# TOP_CTRL_TOP_CTRL_50D80000h register map
Vendor: Texas Instruments
Peripheral module from a debugger description file (folder AM263X).
Registers are 32-bit, read-only, reset 0x0 unless marked. A register's access mark holds for its fields unless they carry their own. Offsets are as the file gives them; lines under a group give offsets from that group; [hi:lo] are bit positions; {n}, {i} and the like mark numbered series; 'fields as' and 'values as' point back to an identical list; <NAME> marks a mode.

## TOP_CTRL
{0x10+4i} TOP_CTRL_EFUSE_DIEID{i} (i=0..3) — Register to read DIEID{i}.
  [31:0] EFUSE_DIEID{i}_VAL — EFUSE DieID[{32i+31}:{32i}]
{0x20+4i} TOP_CTRL_EFUSE_UID{i} (i=0..2) — Register to read UID{i}.
  [31:0] EFUSE_UID{i}_VAL — EFUSE UID[{32i+31}:{32i}]
0x2C TOP_CTRL_EFUSE_UID3 — Register to read UID3.
  [23:0] EFUSE_UID3_VAL — EFUSE UID[120:96]
0x30 TOP_CTRL_EFUSE_DEVICE_TYPE — This register indicates Device Type- High Secure : 0b 1100 1100 (0xA).
  [15:0] EFUSE_DEVICE_TYPE_VAL — EFUSE Device Type
0x34 TOP_CTRL_EFUSE_FROM0_CHECKSUM — The register provides checksum for efuse FROM0.
  [31:0] EFUSE_FROM0_CHECKSUM_VAL — 32 bit FROM0 Checksum
0x38 TOP_CTRL_EFUSE_JTAG_USERCODE_ID — Register to read JTAG user IDCODE.
  [31:0] EFUSE_JTAG_USERCODE_ID_VAL — EFUSE JTAG_USER_CODE_ID[31:0];. Denotes part variant
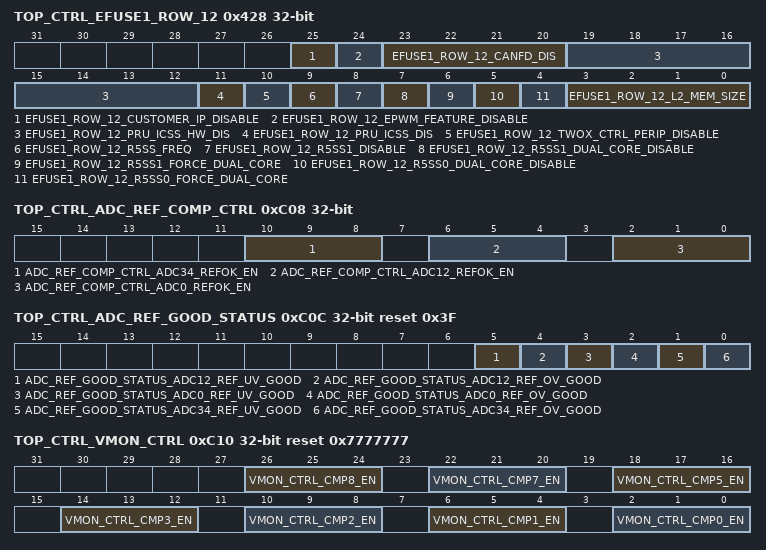
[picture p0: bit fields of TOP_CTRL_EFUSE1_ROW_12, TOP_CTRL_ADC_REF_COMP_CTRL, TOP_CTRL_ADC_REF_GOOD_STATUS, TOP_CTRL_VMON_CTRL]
0x428 TOP_CTRL_EFUSE1_ROW_12 — This register provides details on EFUSE values written into Row 12.
  [25] EFUSE1_ROW_12_CUSTOMER_IP_DISABLE — Customer IP set control0 - All IPs enabled1 - Customer IP set disabled [PWM24-31,CMPSSA6-9,CMPSSB6-9 disabled]
  [24] EFUSE1_ROW_12_EPWM_FEATURE_DISABLE — Customer protected features inside PWM IP 0 - All features enabled1 - Customer defined features are protected
  [23:20] EFUSE1_ROW_12_CANFD_DIS — CANFD disables. Bit positions correspond to CAN instance. 0 - CAN is enabled1 - CAN is disabled
  [19:12] EFUSE1_ROW_12_PRU_ICSS_HW_DIS — ICSSM IP feature configuration0 - ICSSM feature enabled1 - ICSSM feature disabled
  [11] EFUSE1_ROW_12_PRU_ICSS_DIS — ICSSM IP disable0 - ICSSM enabled1 - ICSSM disabled
  [10] EFUSE1_ROW_12_TWOX_CTRL_PERIP_DISABLE — 2x control IPs enabled0 - 1x control IPs
  [9] EFUSE1_ROW_12_R5SS_FREQ — R5SS Freq0 - 400 MHz1 - 200 MHz
  [8] EFUSE1_ROW_12_R5SS1_DISABLE — Supports single R5SS0 cluster, disables R5SS1 cluster
  [7] EFUSE1_ROW_12_R5SS1_DUAL_CORE_DISABLE — Disabling switching to Dual Core mode by the application. Forced lockstep is forced dual core not enabled
  [6] EFUSE1_ROW_12_R5SS1_FORCE_DUAL_CORE — Enable MSS R5FSS1 dual core boot mode. Force Dual core
  [5] EFUSE1_ROW_12_R5SS0_DUAL_CORE_DISABLE — Disabling switching to Dual Core mode by the application. Forced lockstep is forced dual core not enabled
  [4] EFUSE1_ROW_12_R5SS0_FORCE_DUAL_CORE — Enable MSS R5FSS0 dual core boot mode. Force Dual core
  [3:0] EFUSE1_ROW_12_L2_MEM_SIZE — Decides memory size 0000- L2- 2 MB 0001- L2- 1.5 MB 0010- L2- 1 MB 0011- L2- 0.5 MB Others - Reserved
0x500 TOP_CTRL_MAC_ID0 — Ethernet MAC address lower 32-bits.
  [31:0] MAC_ID0_MACID_LO — 48-bit Ethernet MAC_ID field. Can be used by SW through MMR read - MAC ID low [32bits]
0x504 TOP_CTRL_MAC_ID1 — Ethernet MAC address upper 16-bits.
  [15:0] MAC_ID1_MACID_HI — 48-bit Ethernet MAC_ID field. Can be used by SW through MMR read - MAC ID high [16bits]
0xC00 TOP_CTRL_ADC_REFBUF0_CTRL rw — This register is used to enable or disable ADC Reference buffer 0
  [2:0] ADC_REFBUF0_CTRL_ENABLE — Enables adc reference 0, mask hhv before enable000:Disable111 : Enable
0xC04 TOP_CTRL_ADC_REFBUF1_CTRL rw — This register is used to enable or disable ADC Reference buffer 1
  [2:0] ADC_REFBUF1_CTRL_ENABLE — Enables adc reference 1, mask hhv before enable000:Disable111 : Enable
0xC08 TOP_CTRL_ADC_REF_COMP_CTRL rw — This register is used to enable or disable the voltage monitors which measure if the ADC reference voltage is good or not.
  [10:8] ADC_REF_COMP_CTRL_ADC34_REFOK_EN — Enables reference comparators [ROK1]. This monitors adc3 & adc4 refernc
  [6:4] ADC_REF_COMP_CTRL_ADC12_REFOK_EN — Enables reference comparators [ROK0B]. This monitors adc1 & adc2 refernce
  [2:0] ADC_REF_COMP_CTRL_ADC0_REFOK_EN — Enables reference comparators [ROK0]. This monitors adc0 refernce
0xC0C TOP_CTRL_ADC_REF_GOOD_STATUS reset 0x3F — This register shows the status of ADC reference voltages as measured by the ADC Reference OK voltage monitors.
  [5] ADC_REF_GOOD_STATUS_ADC12_REF_UV_GOOD — Under Voltage check OK
  [4] ADC_REF_GOOD_STATUS_ADC12_REF_OV_GOOD — Over voltage check OK
  [3] ADC_REF_GOOD_STATUS_ADC0_REF_UV_GOOD — Under Voltage check OK
  [2] ADC_REF_GOOD_STATUS_ADC0_REF_OV_GOOD — Over voltage check OK
  [1] ADC_REF_GOOD_STATUS_ADC34_REF_UV_GOOD — Under Voltage check OK
  [0] ADC_REF_GOOD_STATUS_ADC34_REF_OV_GOOD — Over voltage check OK
0xC10 TOP_CTRL_VMON_CTRL rw reset 0x7777777 — This register is used to enable or disable the power supply voltage monitors present on the device.
  [26:24] VMON_CTRL_CMP8_EN — VMON EN
  [22:20] VMON_CTRL_CMP7_EN — VMON EN
  [18:16] VMON_CTRL_CMP5_EN — VMON EN
  [4n+2:4n] VMON_CTRL_CMP{n}_EN (n=0..3) — VMON EN
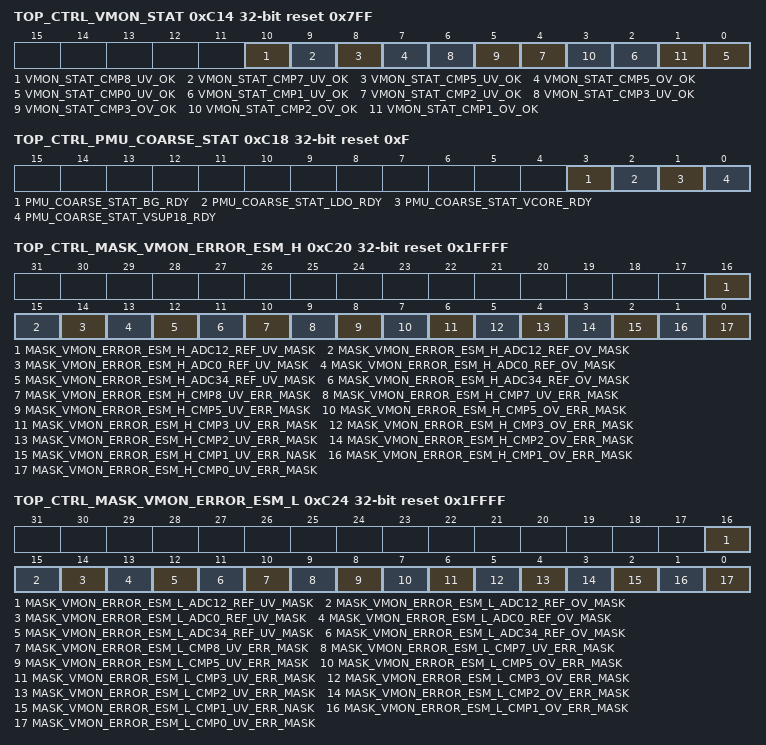
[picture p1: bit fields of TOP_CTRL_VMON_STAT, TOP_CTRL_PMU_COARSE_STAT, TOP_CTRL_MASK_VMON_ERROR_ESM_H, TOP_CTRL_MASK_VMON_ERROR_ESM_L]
0xC14 TOP_CTRL_VMON_STAT reset 0x7FF — This register shows the status output from the voltage monitors present on the device.
  [10] VMON_STAT_CMP8_UV_OK — VMON OK
  [9] VMON_STAT_CMP7_UV_OK — VMON OK
  [8] VMON_STAT_CMP5_UV_OK — VMON OK
  [7] VMON_STAT_CMP5_OV_OK — VMON OK
  [2n] VMON_STAT_CMP{n}_UV_OK (n=0..3) — VMON OK
  [5] VMON_STAT_CMP3_OV_OK — VMON OK
  [3] VMON_STAT_CMP2_OV_OK — VMON OK
  [1] VMON_STAT_CMP1_OV_OK — VMON OK
0xC18 TOP_CTRL_PMU_COARSE_STAT reset 0xF — This register shows the status of coarse voltage monitors present in the device.
  [3] PMU_COARSE_STAT_BG_RDY — Bandgap coarse detection status signals.
  [2] PMU_COARSE_STAT_LDO_RDY — LDO coarse detection status signals.
  [1] PMU_COARSE_STAT_VCORE_RDY — vcore coarse detection status signals.
  [0] PMU_COARSE_STAT_VSUP18_RDY — vdda18 coarse detection status signals.
0xC20 TOP_CTRL_MASK_VMON_ERROR_ESM_H rw reset 0x1FFFF — This register is used to select the voltage monitors whose Error staus should triggering the ESM High Interrupt.
  [16] MASK_VMON_ERROR_ESM_H_ADC12_REF_UV_MASK — VMON Error Mask to ESM
  [15] MASK_VMON_ERROR_ESM_H_ADC12_REF_OV_MASK — VMON Error Mask to ESM
  [14] MASK_VMON_ERROR_ESM_H_ADC0_REF_UV_MASK — VMON Error Mask to ESM
  [13] MASK_VMON_ERROR_ESM_H_ADC0_REF_OV_MASK — VMON Error Mask to ESM
  [12] MASK_VMON_ERROR_ESM_H_ADC34_REF_UV_MASK — VMON Error Mask to ESM
  [11] MASK_VMON_ERROR_ESM_H_ADC34_REF_OV_MASK — VMON Error Mask to ESM
  [10] MASK_VMON_ERROR_ESM_H_CMP8_UV_ERR_MASK — VMON Error Mask to ESM
  [9] MASK_VMON_ERROR_ESM_H_CMP7_UV_ERR_MASK — VMON Error Mask to ESM
  [8] MASK_VMON_ERROR_ESM_H_CMP5_UV_ERR_MASK — VMON Error Mask to ESM
  [7] MASK_VMON_ERROR_ESM_H_CMP5_OV_ERR_MASK — VMON Error Mask to ESM
  [6] MASK_VMON_ERROR_ESM_H_CMP3_UV_ERR_MASK — VMON Error Mask to ESM
  [5] MASK_VMON_ERROR_ESM_H_CMP3_OV_ERR_MASK — VMON Error Mask to ESM
  [4] MASK_VMON_ERROR_ESM_H_CMP2_UV_ERR_MASK — VMON Error Mask to ESM
  [3] MASK_VMON_ERROR_ESM_H_CMP2_OV_ERR_MASK — VMON Error Mask to ESM
  [2] MASK_VMON_ERROR_ESM_H_CMP1_UV_ERR_NASK — VMON Error Mask to ESM
  [1] MASK_VMON_ERROR_ESM_H_CMP1_OV_ERR_MASK — VMON Error Mask to ESM
  [0] MASK_VMON_ERROR_ESM_H_CMP0_UV_ERR_MASK — VMON Error Mask to ESM
0xC24 TOP_CTRL_MASK_VMON_ERROR_ESM_L rw reset 0x1FFFF — This register is used to select the voltage monitors whose Error staus should triggering the ESM Low Interrupt.
  [16] MASK_VMON_ERROR_ESM_L_ADC12_REF_UV_MASK — VMON Error Mask to INTR
  [15] MASK_VMON_ERROR_ESM_L_ADC12_REF_OV_MASK — VMON Error Mask to INTR
  [14] MASK_VMON_ERROR_ESM_L_ADC0_REF_UV_MASK — VMON Error Mask to INTR
  [13] MASK_VMON_ERROR_ESM_L_ADC0_REF_OV_MASK — VMON Error Mask to INTR
  [12] MASK_VMON_ERROR_ESM_L_ADC34_REF_UV_MASK — VMON Error Mask to INTR
  [11] MASK_VMON_ERROR_ESM_L_ADC34_REF_OV_MASK — VMON Error Mask to INTR
  [10] MASK_VMON_ERROR_ESM_L_CMP8_UV_ERR_MASK — VMON Error Mask to INTR
  [9] MASK_VMON_ERROR_ESM_L_CMP7_UV_ERR_MASK — VMON Error Mask to INTR
  [8] MASK_VMON_ERROR_ESM_L_CMP5_UV_ERR_MASK — VMON Error Mask to INTR
  [7] MASK_VMON_ERROR_ESM_L_CMP5_OV_ERR_MASK — VMON Error Mask to INTR
  [6] MASK_VMON_ERROR_ESM_L_CMP3_UV_ERR_MASK — VMON Error Mask to INTR
  [5] MASK_VMON_ERROR_ESM_L_CMP3_OV_ERR_MASK — VMON Error Mask to INTR
  [4] MASK_VMON_ERROR_ESM_L_CMP2_UV_ERR_MASK — VMON Error Mask to INTR
  [3] MASK_VMON_ERROR_ESM_L_CMP2_OV_ERR_MASK — VMON Error Mask to INTR
  [2] MASK_VMON_ERROR_ESM_L_CMP1_UV_ERR_NASK — VMON Error Mask to INTR
  [1] MASK_VMON_ERROR_ESM_L_CMP1_OV_ERR_MASK — VMON Error Mask to INTR
  [0] MASK_VMON_ERROR_ESM_L_CMP0_UV_ERR_MASK — VMON Error Mask to INTR
0xC34 TOP_CTRL_VMON_FILTER_CTRL rw — This register is used to configure the filter present on the Voltage monitor outputs.
  [1:0] VMON_FILTER_CTRL_SELECT_VALUE — VMON FILTER control select00 : no filtering [default]01 : filtering for 4.8us10 : filtering for 9.6us11 : filtering for 14.4us**Note: This bit will only be reset by PORz.
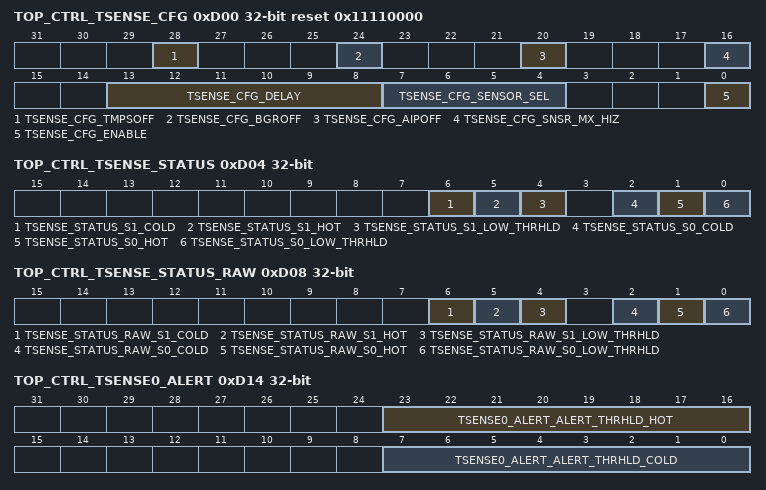
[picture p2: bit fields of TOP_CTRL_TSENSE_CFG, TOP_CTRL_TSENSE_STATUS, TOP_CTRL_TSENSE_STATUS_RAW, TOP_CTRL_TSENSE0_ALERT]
0xD00 TOP_CTRL_TSENSE_CFG rw reset 0x11110000 — This register is used to enable and configure the Temperature sensors present in the device.
  [28] TSENSE_CFG_TMPSOFF — Temperature sensor off0 : on1 : off**Note: This bit will only be reset by PORz.
  [24] TSENSE_CFG_BGROFF — BandGap on/off control 1 : off 0 : on**Note: This bit will only be reset by PORz.
  [20] TSENSE_CFG_AIPOFF — 1 : iddq mode select 0 : normal mode**Note: This bit will only be reset by PORz.
  [16] TSENSE_CFG_SNSR_MX_HIZ — Sensor mux hiz control0 : normal operation. Mux will select either one of the anlaog sensor 1 : mux will be high impedence**Note: This bit will only be reset by PORz.
  [13:8] TSENSE_CFG_DELAY — Number of wait clock cycles between each TMPS Readout. Configure a Non zero value as delay value since configuring 0 is not allowed**Note: This bit will only be reset by PORz.
  [7:4] TSENSE_CFG_SENSOR_SEL — Sensor Selection sensor enable bits for each sensor 0 : sensor disable 1 : sensor enablebit3:temp_sensor3bit2:temp_sensor2bit1:temp_sensor1bit0:temp_sensor0**Note: This bit will only be reset by PORz.
  [0] TSENSE_CFG_ENABLE — Temperature controller enable**Note: This bit will only be reset by PORz.
0xD04 TOP_CTRL_TSENSE_STATUS — This register shows the status of Temperature comparator events which are unmasked.
  [6] TSENSE_STATUS_S1_COLD — temperature Sensor 1 hot event detect0 : event not occured1 : event occurred**Note: This bit will only be reset by PORz.
  [5] TSENSE_STATUS_S1_HOT — temperature Sensor 1 cold event detect0 : event not occured1 : event occurred**Note: This bit will only be reset by PORz.
  [4] TSENSE_STATUS_S1_LOW_THRHLD — temperature Sensor 1 low threshold event detect0 : event not occured1 : event occurred**Note: This bit will only be reset by PORz.
  [2] TSENSE_STATUS_S0_COLD — temperature Sensor 0 hot event detect0 : event not occured1 : event occurred**Note: This bit will only be reset by PORz.
  [1] TSENSE_STATUS_S0_HOT — temperature Sensor 0 cold event detect0 : event not occured1 : event occurred**Note: This bit will only be reset by PORz.
  [0] TSENSE_STATUS_S0_LOW_THRHLD — temperature Sensor 0 low threshold event detect0 : event not occured1 : event occurred**Note: This bit will only be reset by PORz.
0xD08 TOP_CTRL_TSENSE_STATUS_RAW — This register shows the status of all Temperature comparators events including masked events.
  [6] TSENSE_STATUS_RAW_S1_COLD — temperature Sensor 1 hot event detect0 : event not occured1 : event occurred**Note: This bit will only be reset by PORz.
  [5] TSENSE_STATUS_RAW_S1_HOT — temperature Sensor 1 cold event detect0 : event not occured1 : event occurred**Note: This bit will only be reset by PORz.
  [4] TSENSE_STATUS_RAW_S1_LOW_THRHLD — temperature Sensor 1 low threshold event detect0 : event not occured1 : event occurred**Note: This bit will only be reset by PORz.
  [2] TSENSE_STATUS_RAW_S0_COLD — temperature Sensor 0 hot event detect0 : event not occured1 : event occurred**Note: This bit will only be reset by PORz.
  [1] TSENSE_STATUS_RAW_S0_HOT — temperature Sensor 0 cold event detect0 : event not occured1 : event occurred**Note: This bit will only be reset by PORz.
  [0] TSENSE_STATUS_RAW_S0_LOW_THRHLD — temperature Sensor 0 low threshold event detect0 : event not occured1 : event occurred**Note: This bit will only be reset by PORz.
0xD14 TOP_CTRL_TSENSE0_ALERT rw — This register is used to configure the temperature thresholds for Temp Sensor 0 for generating Alert Interrupts.
  [23:16] TSENSE0_ALERT_ALERT_THRHLD_HOT — cold threshold/low temp threshold**Note: This bit will only be reset by PORz.
  [7:0] TSENSE0_ALERT_ALERT_THRHLD_COLD — Hot threshold/high temp threshold**Note: This bit will only be reset by PORz.
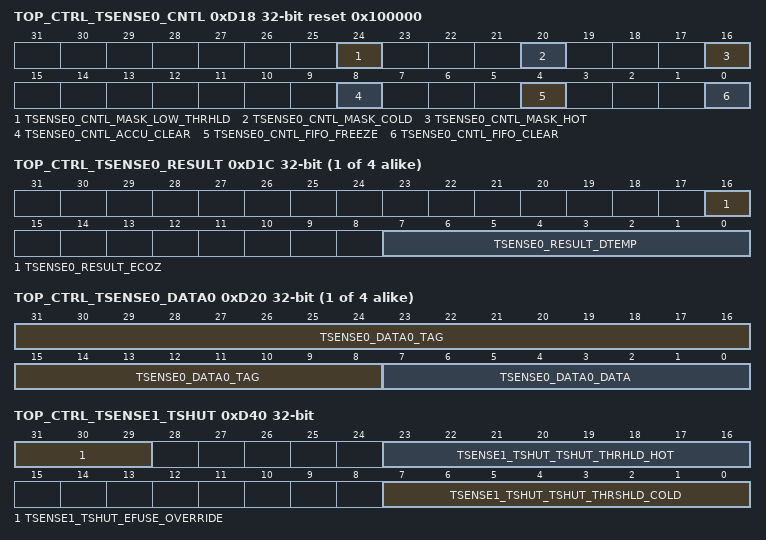
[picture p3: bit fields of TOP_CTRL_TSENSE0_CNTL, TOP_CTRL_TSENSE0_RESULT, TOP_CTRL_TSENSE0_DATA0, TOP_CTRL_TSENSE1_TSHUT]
0xD18 TOP_CTRL_TSENSE0_CNTL rw reset 0x100000 — This register is used to control and configure Temperature sensor 0
  [24] TSENSE0_CNTL_MASK_LOW_THRHLD — mask low threshold comparator output**Note: This bit will only be reset by PORz.
  [20] TSENSE0_CNTL_MASK_COLD — Mask hot comparator output**Note: This bit will only be reset by PORz.
  [16] TSENSE0_CNTL_MASK_HOT — mask cold comparator output**Note: This bit will only be reset by PORz.
  [8] TSENSE0_CNTL_ACCU_CLEAR — Accumulator clear**Note: This bit will only be reset by PORz.
  [4] TSENSE0_CNTL_FIFO_FREEZE — fifo freeze**Note: This bit will only be reset by PORz.
  [0] TSENSE0_CNTL_FIFO_CLEAR — fifo clear**Note: This bit will only be reset by PORz.
{0xD1C+0x30*i} TOP_CTRL_TSENSE{i}_RESULT (i=0..3) — This register shows the most recent temperature readout and status of any ongoing Temperature measurement from Temperature Sensor {i}
  [16] TSENSE{i}_RESULT_ECOZ — Conversion in Progress.1 : Conversion on going0 : conversion completed**Note: This bit will only be reset by PORz.
  [7:0] TSENSE{i}_RESULT_DTEMP — Temp Code readout**Note: This bit will only be reset by PORz.
{0xD20+4i} TOP_CTRL_TSENSE0_DATA{i} (i=0..3) — This register shows Temp Sensor 0 result data in FIFO Register {i}
  [31:8] TSENSE0_DATA{i}_TAG — Timestamp for temperature sesnor 0 Data {i} measured**Note: This bit will only be reset by PORz.
  [7:0] TSENSE0_DATA{i}_DATA — Temperature Sensor0 FIFO data {i}**Note: This bit will only be reset by PORz.
0xD30 TOP_CTRL_TSENSE0_ACCU — Temp Sensor 0 Result Accumulator Register.
  [31:0] TSENSE0_ACCU_CUMUL — cumulative sum of past DTEMPs**Note: This bit will only be reset by PORz.
0xD40 TOP_CTRL_TSENSE1_TSHUT rw — This register is used to override the factory specified Tshut temperature with an application specific Tshut temperature for Temperature sensor 1
  [31:29] TSENSE1_TSHUT_EFUSE_OVERRIDE — Efuse override000 -- Value from EFUSE is used as tshut hot and tshut cold thresholds111 - Overide value takes effect**Note: This bit will only be reset by PORz.
  [23:16] TSENSE1_TSHUT_TSHUT_THRHLD_HOT — tshut hot threshold. Reads efuse value untill overwritten with override = 111**Note: This bit will only be reset by PORz.
  [7:0] TSENSE1_TSHUT_TSHUT_THRSHLD_COLD — tshut cold threshold. Reads efuse value untill overwritten with override = 111**Note: This bit will only be reset by PORz.
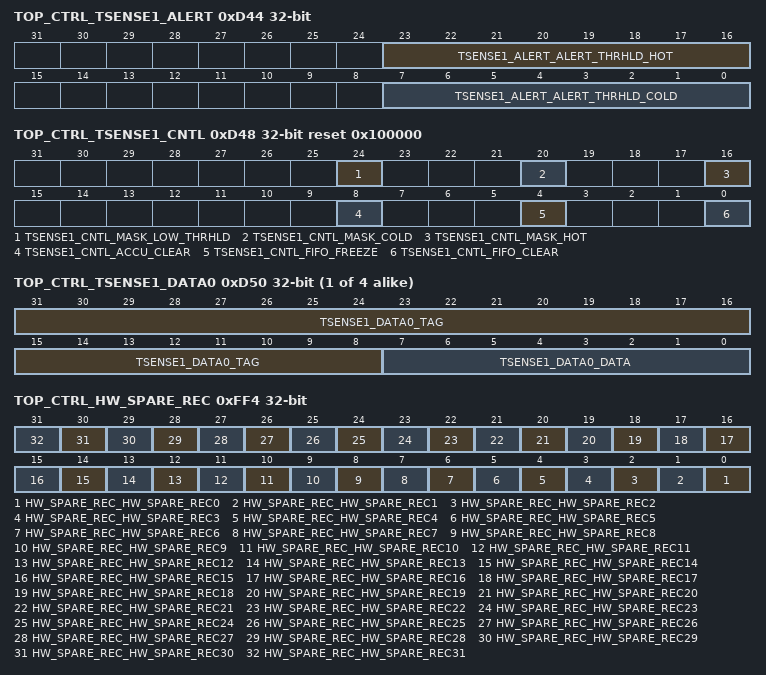
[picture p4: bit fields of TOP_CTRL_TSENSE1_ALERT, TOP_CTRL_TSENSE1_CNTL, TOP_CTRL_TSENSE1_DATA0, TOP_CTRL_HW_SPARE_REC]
0xD44 TOP_CTRL_TSENSE1_ALERT rw — This register is used to configure the temperature thresholds for Temp Sensor 1 for generating Alert Interrupts.
  [23:16] TSENSE1_ALERT_ALERT_THRHLD_HOT — cold threshold/low temp threshold**Note: This bit will only be reset by PORz.
  [7:0] TSENSE1_ALERT_ALERT_THRHLD_COLD — Hot threshold/high temp threshold**Note: This bit will only be reset by PORz.
0xD48 TOP_CTRL_TSENSE1_CNTL rw reset 0x100000 — This register is used to control and configure Temperature sensor 1
  [24] TSENSE1_CNTL_MASK_LOW_THRHLD — mask low threshold comparator output**Note: This bit will only be reset by PORz.
  [20] TSENSE1_CNTL_MASK_COLD — Mask hot comparator output**Note: This bit will only be reset by PORz.
  [16] TSENSE1_CNTL_MASK_HOT — mask cold comparator output**Note: This bit will only be reset by PORz.
  [8] TSENSE1_CNTL_ACCU_CLEAR — Accumulator clear**Note: This bit will only be reset by PORz.
  [4] TSENSE1_CNTL_FIFO_FREEZE — fifo freeze**Note: This bit will only be reset by PORz.
  [0] TSENSE1_CNTL_FIFO_CLEAR — fifo clear**Note: This bit will only be reset by PORz.
{0xD50+4i} TOP_CTRL_TSENSE1_DATA{i} (i=0..3) — This register shows Temp Sensor 1 result data in FIFO Register {i}
  [31:8] TSENSE1_DATA{i}_TAG — Timestamp for temperature sesnor 1 Data {i} measured**Note: This bit will only be reset by PORz.
  [7:0] TSENSE1_DATA{i}_DATA — Temperature sensor 1 FIFO Data {i}**Note: This bit will only be reset by PORz.
0xD60 TOP_CTRL_TSENSE1_ACCU — Temp Sensor 1 Result Accumulator Register.
  [31:0] TSENSE1_ACCU_CUMUL — cumulative sum of past DTEMPs**Note: This bit will only be reset by PORz.
{0xFD0+4i} TOP_CTRL_HW_SPARE_RW{i} rw (i=0..3)
  [31:0] HW_SPARE_RW{i}_HW_SPARE_RW{i} — Reserved for HW R&D
{0xFE0+4i} TOP_CTRL_HW_SPARE_RO{i} (i=0..3)
  [31:0] HW_SPARE_RO{i}_HW_SPARE_RO{i} — Reserved for HW R&D
0xFF0 TOP_CTRL_HW_SPARE_WPH rw
  [31:0] HW_SPARE_WPH_HW_SPARE_WPH — Reserved for HW R&D
0xFF4 TOP_CTRL_HW_SPARE_REC rw
  [n] HW_SPARE_REC_HW_SPARE_REC{n} (n=0..31) — Reserved for HW R&D
0x1008 TOP_CTRL_LOCK0_KICK0 rw — - KICK0 component.
  [31:0] LOCK0_KICK0 — - KICK0 component
0x100C TOP_CTRL_LOCK0_KICK1 rw — - KICK1 component.
  [31:0] LOCK0_KICK1 — - KICK1 component
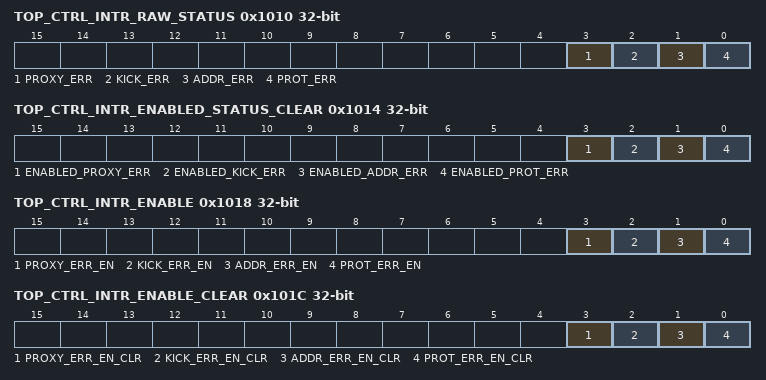
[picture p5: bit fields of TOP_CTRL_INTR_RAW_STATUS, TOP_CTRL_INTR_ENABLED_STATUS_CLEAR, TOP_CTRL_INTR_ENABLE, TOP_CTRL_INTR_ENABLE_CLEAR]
0x1010 TOP_CTRL_INTR_RAW_STATUS access not given — Interrupt Raw Status/Set Register.
  [3] PROXY_ERR — Proxy0 access violation error. Raw status is read. Write a 1 to set the status. Writing a 0 has no effect. (access R/W1TS)
  [2] KICK_ERR — Kick access violation error. Raw status is read. Write a 1 to set the status. Writing a 0 has no effect. (access R/W1TS)
  [1] ADDR_ERR — Addressing violation error. Raw status is read. Write a 1 to set the status. Writing a 0 has no effect. (access R/W1TS)
  [0] PROT_ERR — Protection violation error. Raw status is read. Write a 1 to set the status. Writing a 0 has no effect. (access R/W1TS)
0x1014 TOP_CTRL_INTR_ENABLED_STATUS_CLEAR access not given — Interrupt Enabled Status/Clear register.
  [3] ENABLED_PROXY_ERR — Proxy0 access violation error. Enabled status is read. Write a 1 to clear the status. Writing a 0 has no effect. (access R/W1TC)
  [2] ENABLED_KICK_ERR — Kick access violation error. Enabled status is read. Write a 1 to clear the status. Writing a 0 has no effect. (access R/W1TC)
  [1] ENABLED_ADDR_ERR — Addressing violation error. Enabled status is read. Write a 1 to clear the status. Writing a 0 has no effect. (access R/W1TC)
  [0] ENABLED_PROT_ERR — Protection violation error. Enabled status is read. Write a 1 to clear the status. Writing a 0 has no effect. (access R/W1TC)
0x1018 TOP_CTRL_INTR_ENABLE access not given — Interrupt Enable register.
  [3] PROXY_ERR_EN — Proxy0 access violation error enable. Write a 1 to set the enable. Writing a 0 has no effect. (access R/W1TS)
  [2] KICK_ERR_EN — Kick access violation error enable. Write a 1 to set the enable. Writing a 0 has no effect. (access R/W1TS)
  [1] ADDR_ERR_EN — Addressing violation error enable. Write a 1 to set the enable. Writing a 0 has no effect. (access R/W1TS)
  [0] PROT_ERR_EN — Protection violation error enable. Write a 1 to set the enable. Writing a 0 has no effect. (access R/W1TS)
0x101C TOP_CTRL_INTR_ENABLE_CLEAR access not given — Interrupt Enable Clear register.
  [3] PROXY_ERR_EN_CLR — Proxy0 access violation error enable clear. Write a 1 to clear the enable. Writing a 0 has no effect. (access R/W1TC)
  [2] KICK_ERR_EN_CLR — Kick access violation error enable clear. Write a 1 to clear the enable. Writing a 0 has no effect. (access R/W1TC)
  [1] ADDR_ERR_EN_CLR — Addressing violation error enable clear. Write a 1 to clear the enable. Writing a 0 has no effect. (access R/W1TC)
  [0] PROT_ERR_EN_CLR — Protection violation error enable clear. Write a 1 to clear the enable. Writing a 0 has no effect. (access R/W1TC)
0x1020 TOP_CTRL_EOI rw — EOI register.
  [7:0] EOI_VECTOR — EOI vector value. Write this with interrupt distribution value in the chip.
0x1024 TOP_CTRL_FAULT_ADDRESS — Fault Address register.
  [31:0] FAULT_ADDR — Fault Address.
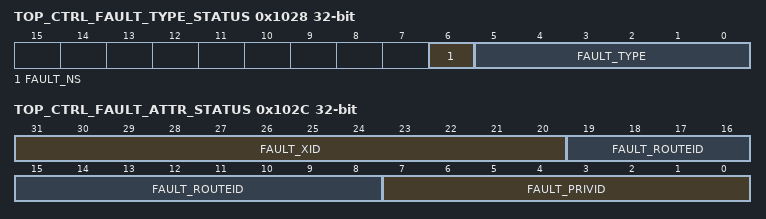
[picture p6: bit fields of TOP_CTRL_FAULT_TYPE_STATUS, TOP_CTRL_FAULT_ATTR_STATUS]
0x1028 TOP_CTRL_FAULT_TYPE_STATUS — Fault Type Status register.
  [6] FAULT_NS — Non-secure access.
  [5:0] FAULT_TYPE — Fault Type 10_0000 = Supervisor read fault - priv = 1 dir = 1 dtype != 1 01_0000 = Supervisor write fault - priv = 1 dir = 0 00_1000 = Supervisor execute fault - priv = 1 dir = 1 dtype = 1 00_0100 = User read fault - priv = 0 dir = 1 dtype = 1 00_0010 = User write fault - priv = 0 dir = 0 00_0001 = User execute fault - priv = 0 dir = 1 dtype = 1 00_0000 = No fault
0x102C TOP_CTRL_FAULT_ATTR_STATUS — Fault Attribute Status register.
  [31:20] FAULT_XID — XID.
  [19:8] FAULT_ROUTEID — Route ID.
  [7:0] FAULT_PRIVID — Privilege ID.
0x1030 TOP_CTRL_FAULT_CLEAR wo — Fault Clear register.
  [0] FAULT_CLR — Fault clear. Writing a 1 clears the current fault. Writing a 0 has no effect.
